# CC2340R5 register map
File version: 1.0
CPU: CM0P 1.0, other endian, MPU, FPU, 3 interrupt priority bits
Registers are 32-bit, read-write, reset 0x0 unless marked. A register's access mark holds for its fields unless they carry their own. Offsets are from the block's base; [hi:lo] are bit positions; {n}, {i} and the like mark numbered series; 'fields as' and 'values as' point back to an identical list.

## SYS0 — This is top module of SYS0 for LOKI
Base 0x40004000
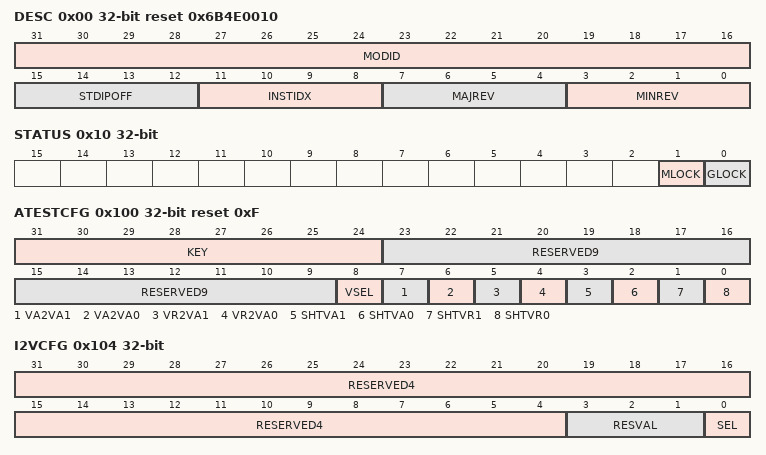
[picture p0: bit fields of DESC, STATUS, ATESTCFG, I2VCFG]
0x00 DESC reset 0x6B4E0010 — Description Register. This register provides IP module ID, revision information, instance index and standard MMR registers offset.
  [31:16] MODID ro — [31:16] Module identifier used to uniquely identify this IP.
  [15:12] STDIPOFF ro — [15:12] Standard IP MMR block offset. Standard IP MMRs are the set of from aggregated IRQ registers till DTB. 0: Standard IP MMRs do not exist 0x1-0xF: Standard IP MMRs begin at offset of (64*STDIPOFF from the base IP address)
  [11:8] INSTIDX ro — [11:8] IP Instance ID number. If multiple instances of IP exist in the device, this field can identify the instance number (0-15).
  [7:4] MAJREV ro — [7:4] Major revision of IP (0-15).
  [3:0] MINREV ro — [3:0] Minor revision of IP (0-15).
0x04 DESCEX reset 0x129 — Extended Description Register. This register provides configuration details of the IP to software drivers and end users.
  [15:0] TBITS ro — [15:0] Total number of trim bits
0x08 GLOCK — Global Lock Register. Locks registers in both mutable and immutable sections
  [0] LOCK wo — [0:0] When LOCK is set, write access to registers in mutable and immutable sections are not allowed. Registers in mutable section can be temporarily unlocked by writing the KEY to MUNLOCK.KEY Following immutable registers are locked by GLOCK.LOCK TESTCFG I2VCFG TSENSCFG LPCMPCFG TIMMUTE0 TIMMUTE1 TIMMUTE2 PARTID LIFECYC
    1=SET (Global Lock is set); 0=NOEFF (No effect)
0x0C MUNLOCK — Unlocks registers in mutable section
  [31:0] KEY wo — [31:0] Write the unlock key 0xC5AF_6927 to temporarily unlock registers in mutable section. The lock is set automatically if no write accesses, to the mutable section, are detected for consecutive 32 CLKULL (24MHz) clock cycles. Writing any value other that the unlock key will immediately lock the mutable register space for write access.
0x10 STATUS — Lock Status Register
  [1] MLOCK ro — [1:1] Lock status of registers in mutable section.
    1=LOCKED (Registers in the mutable section are locked for write); 0=UNLOCKED (Registers in the mutable section are not locked, and are writable)
  [0] GLOCK ro — [0:0] Status of Global lock
    1=LOCKED; 0=UNLOCKED
0x100 ATESTCFG reset 0xF — Internal. Only to be used through TI provided API.
  [31:24] KEY wo — [31:24] Internal. Only to be used through TI provided API.
  [23:9] RESERVED9 ro — [23:9] Internal. Only to be used through TI provided API.
  [8] VSEL — [8:8] Internal. Only to be used through TI provided API.
    1=VDDA (Internal. Only to be used through TI provided API.); 0=VDDBST (Internal. Only to be used through TI provided API.)
  [7] VA2VA1 — [7:7] Internal. Only to be used through TI provided API.
    1=CLOSE (Internal. Only to be used through TI provided API.); 0=OPEN (Internal. Only to be used through TI provided API.)
  [6] VA2VA0 — [6:6] Internal. Only to be used through TI provided API.
    values as VA2VA1
  [5] VR2VA1 — [5:5] Internal. Only to be used through TI provided API.
    values as VA2VA1
  [4] VR2VA0 — [4:4] Internal. Only to be used through TI provided API.
    values as VA2VA1
  [3] SHTVA1 — [3:3] Internal. Only to be used through TI provided API.
    values as VA2VA1
  [2] SHTVA0 — [2:2] Internal. Only to be used through TI provided API.
    values as VA2VA1
  [1] SHTVR1 — [1:1] Internal. Only to be used through TI provided API.
    values as VA2VA1
  [0] SHTVR0 — [0:0] Internal. Only to be used through TI provided API.
    values as VA2VA1
0x104 I2VCFG — Internal. Only to be used through TI provided API.
  [31:4] RESERVED4 ro — [31:4] Internal. Only to be used through TI provided API.
  [3:1] RESVAL — [3:1] Internal. Only to be used through TI provided API.
    7=OFF_RES (Internal. Only to be used through TI provided API.); 6=MO1 (Internal. Only to be used through TI provided API.); 5=KO100 (Internal. Only to be used through TI provided API.); 4=KO50 (Internal. Only to be used through TI provided API.); 3=KO20 (Internal. Only to be used through TI provided API.); 2=KO10 (Internal. Only to be used through TI provided API.); 1=KO2 (Internal. Only to be used through TI provided API.); 0=OFF (Internal. Only to be used through TI provided API.)
  [0] SEL — [0:0] Internal. Only to be used through TI provided API.
    1=VA_ATEST_A0 (Internal. Only to be used through TI provided API.); 0=VR_ATEST_A0 (Internal. Only to be used through TI provided API.)
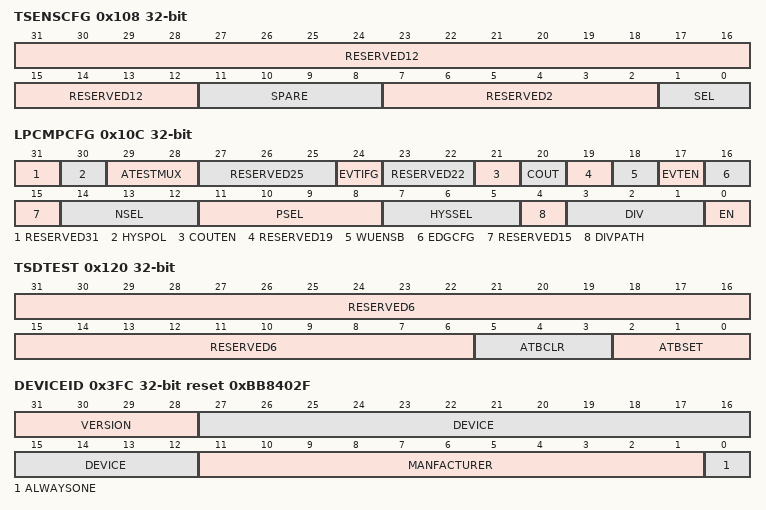
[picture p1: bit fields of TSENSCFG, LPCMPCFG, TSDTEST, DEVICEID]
0x108 TSENSCFG — Internal. Only to be used through TI provided API.
  [31:12] RESERVED12 ro — [31:12] Internal. Only to be used through TI provided API.
  [11:8] SPARE — [11:8] Internal. Only to be used through TI provided API.
  [7:2] RESERVED2 ro — [7:2] Internal. Only to be used through TI provided API.
  [1:0] SEL — [1:0] Internal. Only to be used through TI provided API.
    2=GND (Internal. Only to be used through TI provided API.); 1=VALUE (Internal. Only to be used through TI provided API.); 0=DISABLE (Internal. Only to be used through TI provided API.)
0x10C LPCMPCFG — Internal. Only to be used through TI provided API.
  [31] RESERVED31 ro — [31:31] Internal. Only to be used through TI provided API.
  [30] HYSPOL — [30:30] Internal. Only to be used through TI provided API.
  [29:28] ATESTMUX — [29:28] Internal. Only to be used through TI provided API.
    3=IBIASOUT (Internal. Only to be used through TI provided API.); 2=COMP_VIN_NEG (Internal. Only to be used through TI provided API.); 1=COMPOUT (Internal. Only to be used through TI provided API.); 0=OFF (Internal. Only to be used through TI provided API.)
  [27:25] RESERVED25 ro — [27:25] Internal. Only to be used through TI provided API.
  [24] EVTIFG — [24:24] Internal. Only to be used through TI provided API.
    1=SET (Internal. Only to be used through TI provided API.); 0=CLR (Internal. Only to be used through TI provided API.)
  [23:22] RESERVED22 ro — [23:22] Internal. Only to be used through TI provided API.
  [21] COUTEN — [21:21] Internal. Only to be used through TI provided API.
    1=EN (Internal. Only to be used through TI provided API.); 0=DIS (Internal. Only to be used through TI provided API.)
  [20] COUT ro — [20:20] Internal. Only to be used through TI provided API.
    1=HIGH (Internal. Only to be used through TI provided API.); 0=LOW (Internal. Only to be used through TI provided API.)
  [19] RESERVED19 ro — [19:19] Internal. Only to be used through TI provided API.
  [18] WUENSB — [18:18] Internal. Only to be used through TI provided API.
    values as COUTEN
  [17] EVTEN — [17:17] Internal. Only to be used through TI provided API.
    values as COUTEN
  [16] EDGCFG — [16:16] Internal. Only to be used through TI provided API.
    1=FALL (Internal. Only to be used through TI provided API.); 0=RISE (Internal. Only to be used through TI provided API.)
  [15] RESERVED15 ro — [15:15] Internal. Only to be used through TI provided API.
  [14:12] NSEL — [14:12] Internal. Only to be used through TI provided API.
    4=VDDD (Internal. Only to be used through TI provided API.); 3=VDDA (Internal. Only to be used through TI provided API.); 2=VA_PAD_A3 (Internal. Only to be used through TI provided API.); 1=VA_PAD_A2 (Internal. Only to be used through TI provided API.); 0=OPEN (Internal. Only to be used through TI provided API.)
  [11:8] PSEL — [11:8] Internal. Only to be used through TI provided API.
    8=VDDA (Internal. Only to be used through TI provided API.); 7=VA_ATEST_A1 (Internal. Only to be used through TI provided API.); 6=VA_ATEST_A0 (Internal. Only to be used through TI provided API.); 5=VR_ATEST_A1 (Internal. Only to be used through TI provided API.); 4=VR_ATEST_A0 (Internal. Only to be used through TI provided API.); 3=VA_PAD_A3 (Internal. Only to be used through TI provided API.); 2=VA_PAD_A2 (Internal. Only to be used through TI provided API.); 1=VA_PAD_A1 (Internal. Only to be used through TI provided API.); 0=OPEN (Internal. Only to be used through TI provided API.)
  [7:5] HYSSEL — [7:5] Internal. Only to be used through TI provided API.
    {v}=Internal. Only to be used through TI provided API. (v=0..7)
  [4] DIVPATH — [4:4] Internal. Only to be used through TI provided API.
    1=PSIDE (Internal. Only to be used through TI provided API.); 0=NSIDE (Internal. Only to be used through TI provided API.)
  [3:1] DIV — [3:1] Internal. Only to be used through TI provided API.
    {v}=Internal. Only to be used through TI provided API. (v=0..4)
  [0] EN — [0:0] Internal. Only to be used through TI provided API.
    values as COUTEN
0x120 TSDTEST — Internal. Only to be used through TI provided API.
  [31:6] RESERVED6 ro — [31:6] Internal. Only to be used through TI provided API.
  [5:3] ATBCLR wo — [5:3] Internal. Only to be used through TI provided API.
  [2:0] ATBSET wo — [2:0] Internal. Only to be used through TI provided API.
    7=RESERVED (Internal. Only to be used through TI provided API.); 6=TSDOUT (Internal. Only to be used through TI provided API.); 5=COMPOUT (Internal. Only to be used through TI provided API.); 4=EN_DELAY (Internal. Only to be used through TI provided API.); 3=EA_CUR (Internal. Only to be used through TI provided API.); 2=VREF (Internal. Only to be used through TI provided API.); 1=VSENSE (Internal. Only to be used through TI provided API.); 0=OPEN (Internal. Only to be used through TI provided API.)
0x3FC DEVICEID reset 0xBB8402F — This register provides Device ID information. Note: This 32-bit register value is provided as output to DEBUGSS.
  [31:28] VERSION ro — [31:28] Monotonic increasing value indicating new hardware revision. A newer hardware revision shall never have a lower version than an older revision of hardware.
  [27:12] DEVICE ro — [27:12] Value generated by RAMP for the SOC. This value uniquely identifies the die from any other TI device.
  [11:1] MANFACTURER ro — [11:1] JEP 106 assigned manufacturer ID. This field identifies the device as a Texas Instruments device.
  [0] ALWAYSONE ro — [0:0] Value 1 in this bit field means that a 32-bit scan register exists.
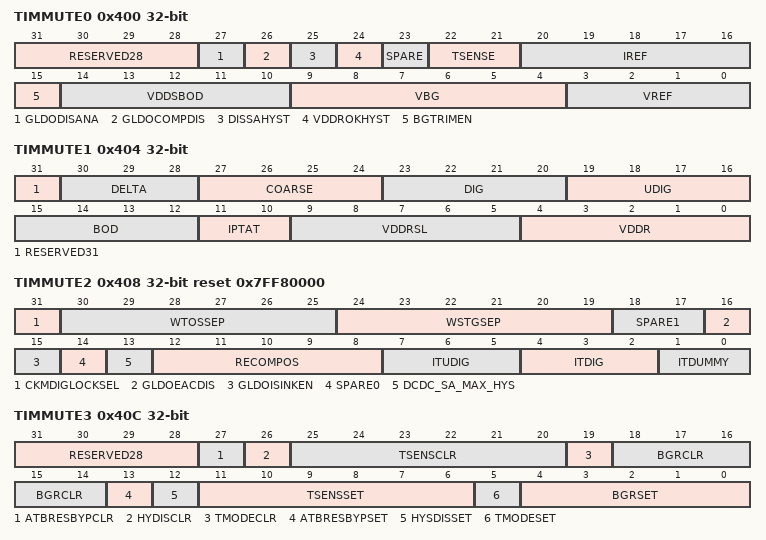
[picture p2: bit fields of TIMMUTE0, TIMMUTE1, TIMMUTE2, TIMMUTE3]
0x400 TIMMUTE0 — Internal. Only to be used through TI provided API.
  [31:28] RESERVED28 ro — [31:28] Internal. Only to be used through TI provided API.
  [27] GLDODISANA — [27:27] Internal. Only to be used through TI provided API.
  [26] GLDOCOMPDIS — [26:26] Internal. Only to be used through TI provided API.
  [25] DISSAHYST — [25:25] Internal. Only to be used through TI provided API.
  [24] VDDROKHYST — [24:24] Internal. Only to be used through TI provided API.
  [23] SPARE — [23:23] Internal. Only to be used through TI provided API.
  [22:21] TSENSE — [22:21] Internal. Only to be used through TI provided API.
  [20:16] IREF — [20:16] Internal. Only to be used through TI provided API.
  [15] BGTRIMEN — [15:15] Internal. Only to be used through TI provided API.
  [14:10] VDDSBOD — [14:10] Internal. Only to be used through TI provided API.
  [9:4] VBG — [9:4] Internal. Only to be used through TI provided API.
  [3:0] VREF — [3:0] Internal. Only to be used through TI provided API.
0x404 TIMMUTE1 — Internal. Only to be used through TI provided API.
  [31] RESERVED31 ro — [31:31] Internal. Only to be used through TI provided API.
  [30:28] DELTA — [30:28] Internal. Only to be used through TI provided API.
  [27:24] COARSE — [27:24] Internal. Only to be used through TI provided API.
  [23:20] DIG — [23:20] Internal. Only to be used through TI provided API.
  [19:16] UDIG — [19:16] Internal. Only to be used through TI provided API.
  [15:12] BOD — [15:12] Internal. Only to be used through TI provided API.
  [11:10] IPTAT — [11:10] Internal. Only to be used through TI provided API.
  [9:5] VDDRSL — [9:5] Internal. Only to be used through TI provided API.
  [4:0] VDDR — [4:0] Internal. Only to be used through TI provided API.
0x408 TIMMUTE2 reset 0x7FF80000 — Internal. Only to be used through TI provided API.
  [31] CKMDIGLOCKSEL — [31:31] Internal. Only to be used through TI provided API.
  [30:25] WTOSSEP — [30:25] Internal. Only to be used through TI provided API.
  [24:19] WSTGSEP — [24:19] Internal. Only to be used through TI provided API.
  [18:17] SPARE1 — [18:17] Internal. Only to be used through TI provided API.
  [16] GLDOEACDIS — [16:16] Internal. Only to be used through TI provided API.
  [15] GLDOISINKEN — [15:15] Internal. Only to be used through TI provided API.
  [14] SPARE0 — [14:14] Internal. Only to be used through TI provided API.
  [13] DCDC_SA_MAX_HYS — [13:13] Internal. Only to be used through TI provided API.
  [12:8] RECOMPOS — [12:8] Internal. Only to be used through TI provided API.
  [7:5] ITUDIG — [7:5] Internal. Only to be used through TI provided API.
  [4:2] ITDIG — [4:2] Internal. Only to be used through TI provided API.
  [1:0] ITDUMMY — [1:0] Internal. Only to be used through TI provided API.
0x40C TIMMUTE3 — Internal. Only to be used through TI provided API.
  [31:28] RESERVED28 ro — [31:28] Internal. Only to be used through TI provided API.
  [27] ATBRESBYPCLR wo — [27:27] Internal. Only to be used through TI provided API.
  [26] HYDISCLR wo — [26:26] Internal. Only to be used through TI provided API.
  [25:20] TSENSCLR wo — [25:20] Internal. Only to be used through TI provided API.
  [19] TMODECLR wo — [19:19] Internal. Only to be used through TI provided API.
  [18:14] BGRCLR wo — [18:14] Internal. Only to be used through TI provided API.
  [13] ATBRESBYPSET wo — [13:13] Internal. Only to be used through TI provided API.
    1=BYPASS (Internal. Only to be used through TI provided API.); 0=CONN (Internal. Only to be used through TI provided API.)
  [12] HYSDISSET wo — [12:12] Internal. Only to be used through TI provided API.
    1=DIS (Internal. Only to be used through TI provided API.); 0=EN (Internal. Only to be used through TI provided API.)
  [11:6] TSENSSET wo — [11:6] Internal. Only to be used through TI provided API.
  [5] TMODESET wo — [5:5] Internal. Only to be used through TI provided API.
    1=ADC (Internal. Only to be used through TI provided API.); 0=ATB (Internal. Only to be used through TI provided API.)
  [4:0] BGRSET wo — [4:0] Internal. Only to be used through TI provided API.
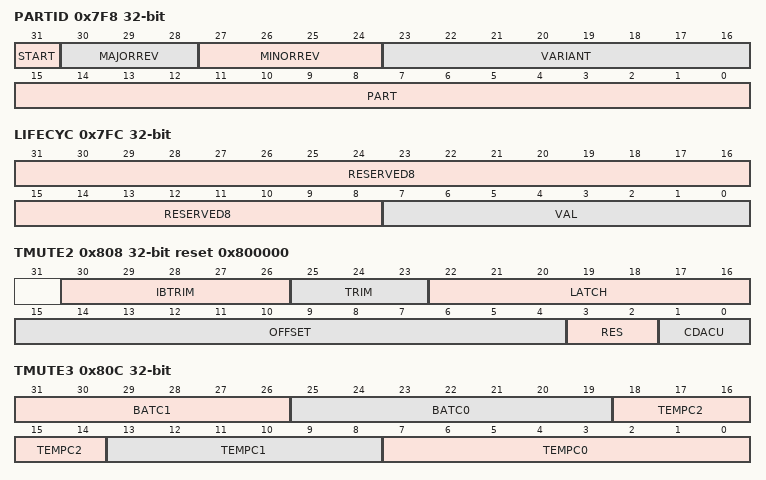
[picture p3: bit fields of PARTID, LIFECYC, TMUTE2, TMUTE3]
0x7F8 PARTID — Internal. Only to be used through TI provided API.
  [31] START — [31:31] Internal. Only to be used through TI provided API.
    values as LPCMPCFG.EVTIFG
  [30:28] MAJORREV — [30:28] Internal. Only to be used through TI provided API.
  [27:24] MINORREV — [27:24] Internal. Only to be used through TI provided API.
  [23:16] VARIANT — [23:16] Internal. Only to be used through TI provided API.
  [15:0] PART — [15:0] Internal. Only to be used through TI provided API.
0x7FC LIFECYC — Internal. Only to be used through TI provided API.
  [31:8] RESERVED8 ro — [31:8] Internal. Only to be used through TI provided API.
  [7:0] VAL — [7:0] Internal. Only to be used through TI provided API.
    255=LCYCLE_ILLEGAL (Internal. Only to be used through TI provided API.); 6=LCYCLE_RETEST (Internal. Only to be used through TI provided API.); 5=LCYCLE_PRODDEV (Internal. Only to be used through TI provided API.); 4=LCYCLE_ENGRDEV (Internal. Only to be used through TI provided API.); 3=LCYCLE_TESTFT (Internal. Only to be used through TI provided API.); 2=LCYCLE_TESTPT (Internal. Only to be used through TI provided API.); 1=LCYCLE_1STBDAY (Internal. Only to be used through TI provided API.); 0=LCYCLE_POSSIBLE_1STBDAY (Internal. Only to be used through TI provided API.)
0x800 TMUTE0 — TMUTE0 trim Register
  [31:0] CDACL — [31:0] SOCADC: Lower 32 bits of CDAC trim. These bits are used in DTC.
0x804 TMUTE1 — TMUTE1 trim Register
  [31:0] CDACM — [31:0] SOCADC: Middle 32 bits of CDAC trim. These bits are used in DTC.
0x808 TMUTE2 reset 0x800000 — TMUTE2 trim Register
  [30:26] IBTRIM — [30:26] LPCOMP: Bias current trim, 250nA to be terminated across I2V, 1M ohm setting. Resulting target trim voltage 250mV.
  [25:23] TRIM — [25:23] ADC REFBUF trim bits.
  [22:16] LATCH — [22:16] SOC ADC: Latch trim bits. These bits are used in the analog IP.
  [15:4] OFFSET — [15:4] SOCADC: Offset trim bits. These bits are used in DTC.
  [3:2] RES — [3:2] SOCADC: Resistor trim bits. These bits are used in the analog IP.
  [1:0] CDACU — [1:0] SOCADC: Upper 2 bits of CDAC trim. These bits are used in DTC.
0x80C TMUTE3 — TMUTE3 trim Register
  [31:26] BATC1 — [31:26] BATMON: Battery calculation coefficient 1
  [25:19] BATC0 — [25:19] BATMON: Battery calculation coefficient 0
  [18:14] TEMPC2 — [18:14] BATMON: Temperature calculation coefficient 2
  [13:8] TEMPC1 — [13:8] BATMON: Temperature calculation coefficient 1
  [7:0] TEMPC0 — [7:0] BATMON: Temperature calculation coefficient 0
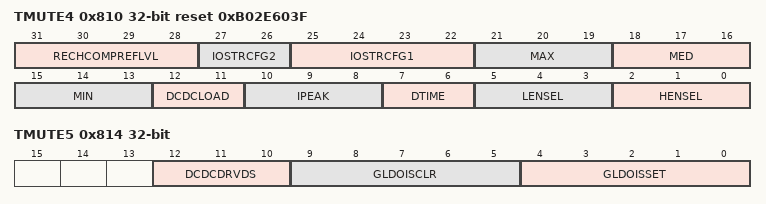
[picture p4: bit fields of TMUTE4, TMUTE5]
0x810 TMUTE4 reset 0xB02E603F — TMUTE4 trim Register
  [31:28] RECHCOMPREFLVL — [31:28] PMUREG: Recharge comparator reference level. Valid values are 0x2 to 0xA. Recommended default value is 0x9. Setting 0x2 corresponds to VDDR = 1.35V and 0xA corresponds to VDDR = 1.47V with 15mV linear increase for every step.
  [27:26] IOSTRCFG2 — [27:26] BATMON: IO drive strength conversion parameter for the second stage
  [25:22] IOSTRCFG1 — [25:22] BATMON: IO drive strength conversion parameter for the first stage
  [21:19] MAX — [21:19] IOC: Maximum IO drive strength
  [18:16] MED — [18:16] IOC: Medium IO drive strength
  [15:13] MIN — [15:13] IOC: Minimum IO drive strength
  [12:11] DCDCLOAD — [12:11] DCDC: Set DCDC load current threshold
  [10:8] IPEAK — [10:8] DCDC: Set inductor peak current
  [7:6] DTIME — [7:6] DCDC: Dead time trim
  [5:3] LENSEL — [5:3] DCDC: Control NMOS switch strength
  [2:0] HENSEL — [2:0] DCDC: Control PMOS switch strength
0x814 TMUTE5 — TMUTE5 trim Register
  [12:10] DCDCDRVDS — [12:10] DCDC: Driver drive strength configuration
  [9:5] GLDOISCLR wo — [9:5] GLDO current source trim clear value
  [4:0] GLDOISSET wo — [4:0] GLDO current source trim set value
